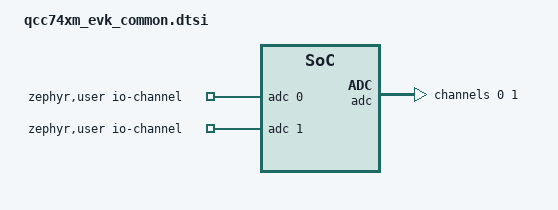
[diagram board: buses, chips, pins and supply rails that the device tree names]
/*
 * Copyright (c) 2026 Qualcomm Technologies, Inc. and/or its subsidiaries
 * SPDX-License-Identifier: Apache-2.0
 */

/ {
	zephyr,user {
		io-channels = <&adc 0>, <&adc 1>;
	};
	aliases {
		adc0 = &adc;
	};
};

&pinctrl {
	adc_default: adc_default {
		group1 {
			pinmux = <GPIO27_ADC_CH10>,
				 <GPIO20_ADC_CH0>;
			input-enable;
			input-schmitt-enable;
		};
	};
};

&dma {
	status = "okay";
};

&adc {
	status = "okay";
	pinctrl-0 = <&adc_default>;
	pinctrl-names = "default";
	dmas = <&dma 0  DMA_REQUEST_ADC  DMA_ADDR_ADC_RDR>;

	#address-cells = <1>;
	#size-cells = <0>;

	channel@0 {
		reg = <0>;
		zephyr,gain = "ADC_GAIN_1";
		zephyr,reference = "ADC_REF_INTERNAL";
		zephyr,acquisition-time = <ADC_ACQ_TIME_DEFAULT>;
		zephyr,input-positive = <ADC_CHANNEL_GND>;
		zephyr,input-negative = <ADC_CHANNEL_10>;
		zephyr,resolution = <16>;
	};

	channel@1 {
		reg = <1>;
		zephyr,gain = "ADC_GAIN_1";
		zephyr,reference = "ADC_REF_INTERNAL";
		zephyr,acquisition-time = <ADC_ACQ_TIME_DEFAULT>;
		zephyr,input-positive = <ADC_CHANNEL_0>;
		zephyr,input-negative = <ADC_CHANNEL_GND>;
		zephyr,resolution = <16>;
	};
};
